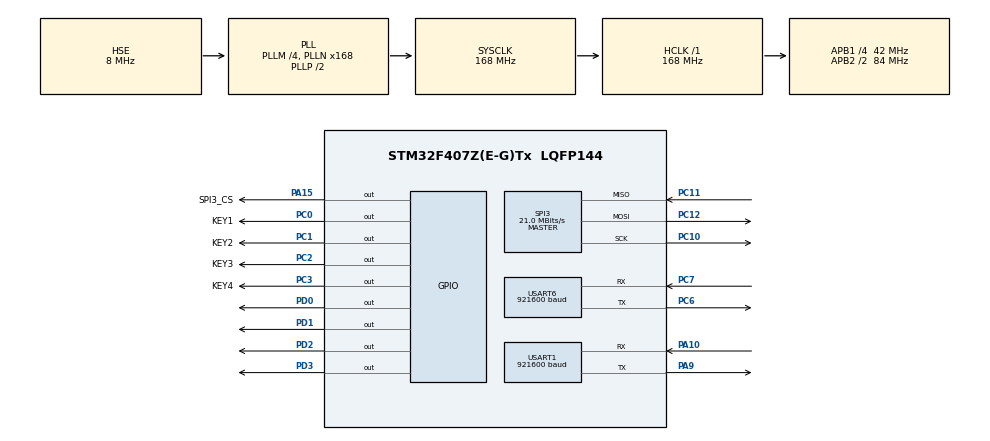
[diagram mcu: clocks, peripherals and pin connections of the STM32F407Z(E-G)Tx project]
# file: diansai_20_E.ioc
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Mcu.Family=STM32F4
PH0-OSC_IN.Signal=RCC_OSC_IN
RCC.CortexFreq_Value=168000000
SPI3.Direction=SPI_DIRECTION_2LINES
SPI3.VirtualType=VM_MASTER
PD3.PinState=GPIO_PIN_SET
USART1.BaudRate=921600
PC10.Signal=SPI3_SCK
PC12.Signal=SPI3_MOSI
PC0.GPIO_Label=KEY1
PD2.GPIO_Speed=GPIO_SPEED_FREQ_HIGH
PC2.GPIO_Speed=GPIO_SPEED_FREQ_HIGH
PD3.GPIO_Speed=GPIO_SPEED_FREQ_HIGH
PC3.GPIO_Speed=GPIO_SPEED_FREQ_HIGH
RCC.SYSCLKSource=RCC_SYSCLKSOURCE_PLLCLK
ProjectManager.StackSize=0x400
PC3.PinState=GPIO_PIN_SET
PA15.GPIO_Label=SPI3_CS
RCC.HCLKFreq_Value=168000000
RCC.APB2TimFreq_Value=168000000
PC7.Signal=USART6_RX
PC3.Signal=GPIO_Output
PD0.Signal=GPIO_Output
PC1.PinState=GPIO_PIN_RESET
RCC.AHBFreq_Value=168000000
PH0-OSC_IN.Mode=HSE-External-Oscillator
SPI3.DataSize=SPI_DATASIZE_16BIT
RCC.HSE_VALUE=8000000
PD0.PinState=GPIO_PIN_SET
PD1.GPIO_Speed=GPIO_SPEED_FREQ_HIGH
PA14.Mode=Serial_Wire
VP_TIM1_VS_ClockSourceINT.Mode=Internal
PH1-OSC_OUT.Mode=HSE-External-Oscillator
Mcu.Package=LQFP144
SPI3.Mode=SPI_MODE_MASTER
USART6.VirtualMode=VM_ASYNC
PA10.Signal=USART1_RX
PA15.Signal=GPIO_Output
USART6.BaudRate=921600
PC11.Mode=Full_Duplex_Master
RCC.APB2CLKDivider=RCC_HCLK_DIV2
RCC.APB1TimFreq_Value=84000000
TIM1.Period=2624
PD3.GPIO_PuPd=GPIO_PULLUP
NVIC.USART1_IRQn=true\:0\:0\:false\:false\:true\:true\:true
PC2.GPIO_Label=KEY3
PC0.PinState=GPIO_PIN_RESET
RCC.PLLSourceVirtual=RCC_PLLSOURCE_HSE
PA10.Mode=Asynchronous
PD2.GPIO_PuPd=GPIO_PULLUP
PC11.Signal=SPI3_MISO
PD3.Signal=GPIO_Output
PC2.Signal=GPIO_Output
PC6.Signal=USART6_TX
PC10.Mode=Full_Duplex_Master
PD1.Signal=GPIO_Output
PD1.GPIO_PuPd=GPIO_PULLUP
PC0.Signal=GPIO_Output
RCC.APB1CLKDivider=RCC_HCLK_DIV4
PD0.GPIO_Speed=GPIO_SPEED_FREQ_HIGH
NVIC.USART6_IRQn=true\:0\:0\:false\:false\:true\:true\:true
PA13.Signal=SYS_JTMS-SWDIO
PA9.Mode=Asynchronous
PC0.GPIO_Speed=GPIO_SPEED_FREQ_HIGH
ProjectManager.TargetToolchain=STM32CubeIDE
PC6.Mode=Asynchronous
PA9.Signal=USART1_TX
RCC.LSE_VALUE=32768
PD2.PinState=GPIO_PIN_SET
PC12.Mode=Full_Duplex_Master
board=custom
SPI3.CLKPhase=SPI_PHASE_2EDGE
RCC.VCOOutputFreq_Value=336000000
PA15.PinState=GPIO_PIN_SET
RCC.APB2Freq_Value=84000000
SPI3.CalculateBaudRate=21.0 MBits/s
PC1.GPIO_Label=KEY2
PH1-OSC_OUT.Signal=RCC_OSC_OUT
PC1.GPIO_Speed=GPIO_SPEED_FREQ_HIGH
PA13.Mode=Serial_Wire
Mcu.Name=STM32F407Z(E-G)Tx
RCC.48MHZClocksFreq_Value=84000000
RCC.SYSCLKFreq_VALUE=168000000
PC2.PinState=GPIO_PIN_RESET
USART1.VirtualMode=VM_ASYNC
PA15.GPIO_Speed=GPIO_SPEED_FREQ_VERY_HIGH
PD1.PinState=GPIO_PIN_SET
PA14.Signal=SYS_JTCK-SWCLK
ProjectManager.HeapSize=0x200
PD0.GPIO_PuPd=GPIO_PULLUP
NVIC.TIM1_UP_TIM10_IRQn=true\:2\:0\:true\:false\:true\:true\:true
RCC.HSI_VALUE=16000000
NVIC.PriorityGroup=NVIC_PRIORITYGROUP_4
RCC.PLLM=4
RCC.PLLN=168
PC3.GPIO_Label=KEY4
PC7.Mode=Asynchronous
PD2.Signal=GPIO_Output
RCC.APB1Freq_Value=42000000
PC1.Signal=GPIO_Output

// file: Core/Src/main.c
/* USER CODE BEGIN Header */
/**
  ******************************************************************************
  * @file           : main.c
  * @brief          : Main program body
  ******************************************************************************
  * @attention
  *
  * <h2><center>&copy; Copyright (c) 2021 STMicroelectronics.
  * All rights reserved.</center></h2>
  *
  * This software component is licensed by ST under BSD 3-Clause license,
  * the "License"; You may not use this file except in compliance with the
  * License. You may obtain a copy of the License at:
  *                        opensource.org/licenses/BSD-3-Clause
  *
  ******************************************************************************
  */
/* USER CODE END Header */
#include "main.h"

/* USER CODE BEGIN PTD */

//本函数对长为N的实数数组先进⾏FFT计算，由于只计算了前�????半幅频，故输出结果仍为N，频率截⽌到Fs/2�????.
arm_rfft_fast_instance_f32 S;

uint8_t isShow=0;

//ch1采样�???????
float dataCh1[2048];

//FFT
float dataCh1FFT[2048];

//显示次数
uint32_t showtimes=0;

//失真类型    0  无失�??     1
uint8_t Dtype=0;

/* USER CODE END PTD */

SPI_HandleTypeDef hspi3;

TIM_HandleTypeDef htim1;

UART_HandleTypeDef huart1;
UART_HandleTypeDef huart6;

void SystemClock_Config(void);
static void MX_GPIO_Init(void);
static void MX_TIM1_Init(void);
static void MX_SPI3_Init(void);
static void MX_USART1_UART_Init(void);
static void MX_USART6_UART_Init(void);

int main(void)
{

  /* MCU Configuration--------------------------------------------------------*/

  /* Reset of all peripherals, Initializes the Flash interface and the Systick. */
  HAL_Init();

  /* Configure the system clock */
  SystemClock_Config();

  /* Initialize all configured peripherals */
  MX_GPIO_Init();
  MX_TIM1_Init();
  MX_SPI3_Init();
  MX_USART1_UART_Init();
  MX_USART6_UART_Init();
  /* USER CODE BEGIN 2 */

  ADS8688_Init(&ads,&hspi3,SPI3_CS_GPIO_Port, SPI3_CS_Pin);

  //HAL_TIM_Base_Start_IT(&htim1);

//
//  HAL_GPIO_WritePin(GPIOC, GPIO_PIN_0, RESET);
//  HAL_GPIO_WritePin(GPIOC, GPIO_PIN_1, RESET);
//  HAL_GPIO_WritePin(GPIOC, GPIO_PIN_2, RESET);
//  HAL_GPIO_WritePin(GPIOC, GPIO_PIN_3, SET);

  arm_rfft_fast_init_f32(&S,FFT_SIZE);//初始化该结构
  HAL_TIM_Base_Start_IT(&htim1);
  HAL_UART_Receive_IT(TFT_RECEIVE, (uint8_t *)&R_onedata, 1);

  /* USER CODE END 2 */

  /* Infinite loop */
  /* USER CODE BEGIN WHILE */
  while (1)
  {
//	  HAL_UART_Transmit(&huart6, ads_data, 2,5);
//	  HAL_UART_Transmit(&huart6, "\0\0", 2,5);

    /* USER CODE END WHILE */

  }
}

void SystemClock_Config(void)
{
  RCC_OscInitTypeDef RCC_OscInitStruct = {0};
  RCC_ClkInitTypeDef RCC_ClkInitStruct = {0};

  /** Configure the main internal regulator output voltage
  */
  __HAL_RCC_PWR_CLK_ENABLE();
  __HAL_PWR_VOLTAGESCALING_CONFIG(PWR_REGULATOR_VOLTAGE_SCALE1);
  /** Initializes the RCC Oscillators according to the specified parameters
  * in the RCC_OscInitTypeDef structure.
  */
  RCC_OscInitStruct.OscillatorType = RCC_OSCILLATORTYPE_HSE;
  RCC_OscInitStruct.HSEState = RCC_HSE_ON;
  RCC_OscInitStruct.PLL.PLLState = RCC_PLL_ON;
  RCC_OscInitStruct.PLL.PLLSource = RCC_PLLSOURCE_HSE;
  RCC_OscInitStruct.PLL.PLLM = 4;
  RCC_OscInitStruct.PLL.PLLN = 168;
  RCC_OscInitStruct.PLL.PLLP = RCC_PLLP_DIV2;
  RCC_OscInitStruct.PLL.PLLQ = 4;
  if (HAL_RCC_OscConfig(&RCC_OscInitStruct) != HAL_OK)
  {
    Error_Handler();
  }
  /** Initializes the CPU, AHB and APB buses clocks
  */
  RCC_ClkInitStruct.ClockType = RCC_CLOCKTYPE_HCLK|RCC_CLOCKTYPE_SYSCLK
                              |RCC_CLOCKTYPE_PCLK1|RCC_CLOCKTYPE_PCLK2;
  RCC_ClkInitStruct.SYSCLKSource = RCC_SYSCLKSOURCE_PLLCLK;
  RCC_ClkInitStruct.AHBCLKDivider = RCC_SYSCLK_DIV1;
  RCC_ClkInitStruct.APB1CLKDivider = RCC_HCLK_DIV4;
  RCC_ClkInitStruct.APB2CLKDivider = RCC_HCLK_DIV2;

  if (HAL_RCC_ClockConfig(&RCC_ClkInitStruct, FLASH_LATENCY_5) != HAL_OK)
  {
    Error_Handler();
  }
}

static void MX_SPI3_Init(void)
{

  /* SPI3 parameter configuration*/
  hspi3.Instance = SPI3;
  hspi3.Init.Mode = SPI_MODE_MASTER;
  hspi3.Init.Direction = SPI_DIRECTION_2LINES;
  hspi3.Init.DataSize = SPI_DATASIZE_16BIT;
  hspi3.Init.CLKPolarity = SPI_POLARITY_LOW;
  hspi3.Init.CLKPhase = SPI_PHASE_2EDGE;
  hspi3.Init.NSS = SPI_NSS_SOFT;
  hspi3.Init.BaudRatePrescaler = SPI_BAUDRATEPRESCALER_2;
  hspi3.Init.FirstBit = SPI_FIRSTBIT_MSB;
  hspi3.Init.TIMode = SPI_TIMODE_DISABLE;
  hspi3.Init.CRCCalculation = SPI_CRCCALCULATION_DISABLE;
  hspi3.Init.CRCPolynomial = 10;
  if (HAL_SPI_Init(&hspi3) != HAL_OK)
  {
    Error_Handler();
  }

}

static void MX_TIM1_Init(void)
{

  TIM_ClockConfigTypeDef sClockSourceConfig = {0};
  TIM_MasterConfigTypeDef sMasterConfig = {0};

  htim1.Instance = TIM1;
  htim1.Init.Prescaler = 0;
  htim1.Init.CounterMode = TIM_COUNTERMODE_UP;
  htim1.Init.Period = 2624;
  htim1.Init.ClockDivision = TIM_CLOCKDIVISION_DIV1;
  htim1.Init.RepetitionCounter = 0;
  htim1.Init.AutoReloadPreload = TIM_AUTORELOAD_PRELOAD_DISABLE;
  if (HAL_TIM_Base_Init(&htim1) != HAL_OK)
  {
    Error_Handler();
  }
  sClockSourceConfig.ClockSource = TIM_CLOCKSOURCE_INTERNAL;
  if (HAL_TIM_ConfigClockSource(&htim1, &sClockSourceConfig) != HAL_OK)
  {
    Error_Handler();
  }
  sMasterConfig.MasterOutputTrigger = TIM_TRGO_RESET;
  sMasterConfig.MasterSlaveMode = TIM_MASTERSLAVEMODE_DISABLE;
  if (HAL_TIMEx_MasterConfigSynchronization(&htim1, &sMasterConfig) != HAL_OK)
  {
    Error_Handler();
  }

}

static void MX_USART1_UART_Init(void)
{

  huart1.Instance = USART1;
  huart1.Init.BaudRate = 921600;
  huart1.Init.WordLength = UART_WORDLENGTH_8B;
  huart1.Init.StopBits = UART_STOPBITS_1;
  huart1.Init.Parity = UART_PARITY_NONE;
  huart1.Init.Mode = UART_MODE_TX_RX;
  huart1.Init.HwFlowCtl = UART_HWCONTROL_NONE;
  huart1.Init.OverSampling = UART_OVERSAMPLING_16;
  if (HAL_UART_Init(&huart1) != HAL_OK)
  {
    Error_Handler();
  }

}

static void MX_USART6_UART_Init(void)
{

  huart6.Instance = USART6;
  huart6.Init.BaudRate = 921600;
  huart6.Init.WordLength = UART_WORDLENGTH_8B;
  huart6.Init.StopBits = UART_STOPBITS_1;
  huart6.Init.Parity = UART_PARITY_NONE;
  huart6.Init.Mode = UART_MODE_TX_RX;
  huart6.Init.HwFlowCtl = UART_HWCONTROL_NONE;
  huart6.Init.OverSampling = UART_OVERSAMPLING_16;
  if (HAL_UART_Init(&huart6) != HAL_OK)
  {
    Error_Handler();
  }

}

static void MX_GPIO_Init(void)
{
  GPIO_InitTypeDef GPIO_InitStruct = {0};

  /* GPIO Ports Clock Enable */
  __HAL_RCC_GPIOH_CLK_ENABLE();
  __HAL_RCC_GPIOC_CLK_ENABLE();
  __HAL_RCC_GPIOA_CLK_ENABLE();
  __HAL_RCC_GPIOD_CLK_ENABLE();

  /*Configure GPIO pin Output Level */
  HAL_GPIO_WritePin(GPIOC, KEY1_Pin|KEY2_Pin|KEY3_Pin, GPIO_PIN_RESET);

  /*Configure GPIO pin Output Level */
  HAL_GPIO_WritePin(KEY4_GPIO_Port, KEY4_Pin, GPIO_PIN_SET);

  /*Configure GPIO pin Output Level */
  HAL_GPIO_WritePin(SPI3_CS_GPIO_Port, SPI3_CS_Pin, GPIO_PIN_SET);

  /*Configure GPIO pin Output Level */
  HAL_GPIO_WritePin(GPIOD, GPIO_PIN_0|GPIO_PIN_1|GPIO_PIN_2|GPIO_PIN_3, GPIO_PIN_SET);

  /*Configure GPIO pins : KEY1_Pin KEY2_Pin KEY3_Pin KEY4_Pin */
  GPIO_InitStruct.Pin = KEY1_Pin|KEY2_Pin|KEY3_Pin|KEY4_Pin;
  GPIO_InitStruct.Mode = GPIO_MODE_OUTPUT_PP;
  GPIO_InitStruct.Pull = GPIO_NOPULL;
  GPIO_InitStruct.Speed = GPIO_SPEED_FREQ_HIGH;
  HAL_GPIO_Init(GPIOC, &GPIO_InitStruct);

  /*Configure GPIO pin : SPI3_CS_Pin */
  GPIO_InitStruct.Pin = SPI3_CS_Pin;
  GPIO_InitStruct.Mode = GPIO_MODE_OUTPUT_PP;
  GPIO_InitStruct.Pull = GPIO_NOPULL;
  GPIO_InitStruct.Speed = GPIO_SPEED_FREQ_VERY_HIGH;
  HAL_GPIO_Init(SPI3_CS_GPIO_Port, &GPIO_InitStruct);

  /*Configure GPIO pins : PD0 PD1 PD2 PD3 */
  GPIO_InitStruct.Pin = GPIO_PIN_0|GPIO_PIN_1|GPIO_PIN_2|GPIO_PIN_3;
  GPIO_InitStruct.Mode = GPIO_MODE_OUTPUT_PP;
  GPIO_InitStruct.Pull = GPIO_PULLUP;
  GPIO_InitStruct.Speed = GPIO_SPEED_FREQ_HIGH;
  HAL_GPIO_Init(GPIOD, &GPIO_InitStruct);

}

void Error_Handler(void)
{
  __disable_irq();
  while (1)
  {
  }
}

/************************ (C) COPYRIGHT STMicroelectronics *****END OF FILE****/
